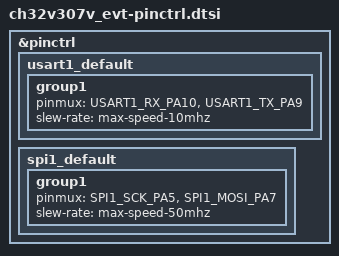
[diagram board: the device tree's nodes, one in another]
/*
 * Copyright (c) 2021, TODO
 * SPDX-License-Identifier: Apache-2.0
 */

#include <dt-bindings/pinctrl/ch32v30x-vc-pinctrl.h>

&pinctrl {

    usart1_default: usart1_default {
		group1{
			pinmux = <USART1_RX_PA10>, <USART1_TX_PA9>;
			slew-rate = "max-speed-10mhz";
		};
	};

	spi1_default: spi1_default {
		group1{
			pinmux = <SPI1_SCK_PA5>, <SPI1_MOSI_PA7>;
			slew-rate = "max-speed-50mhz";
		};
	};

};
